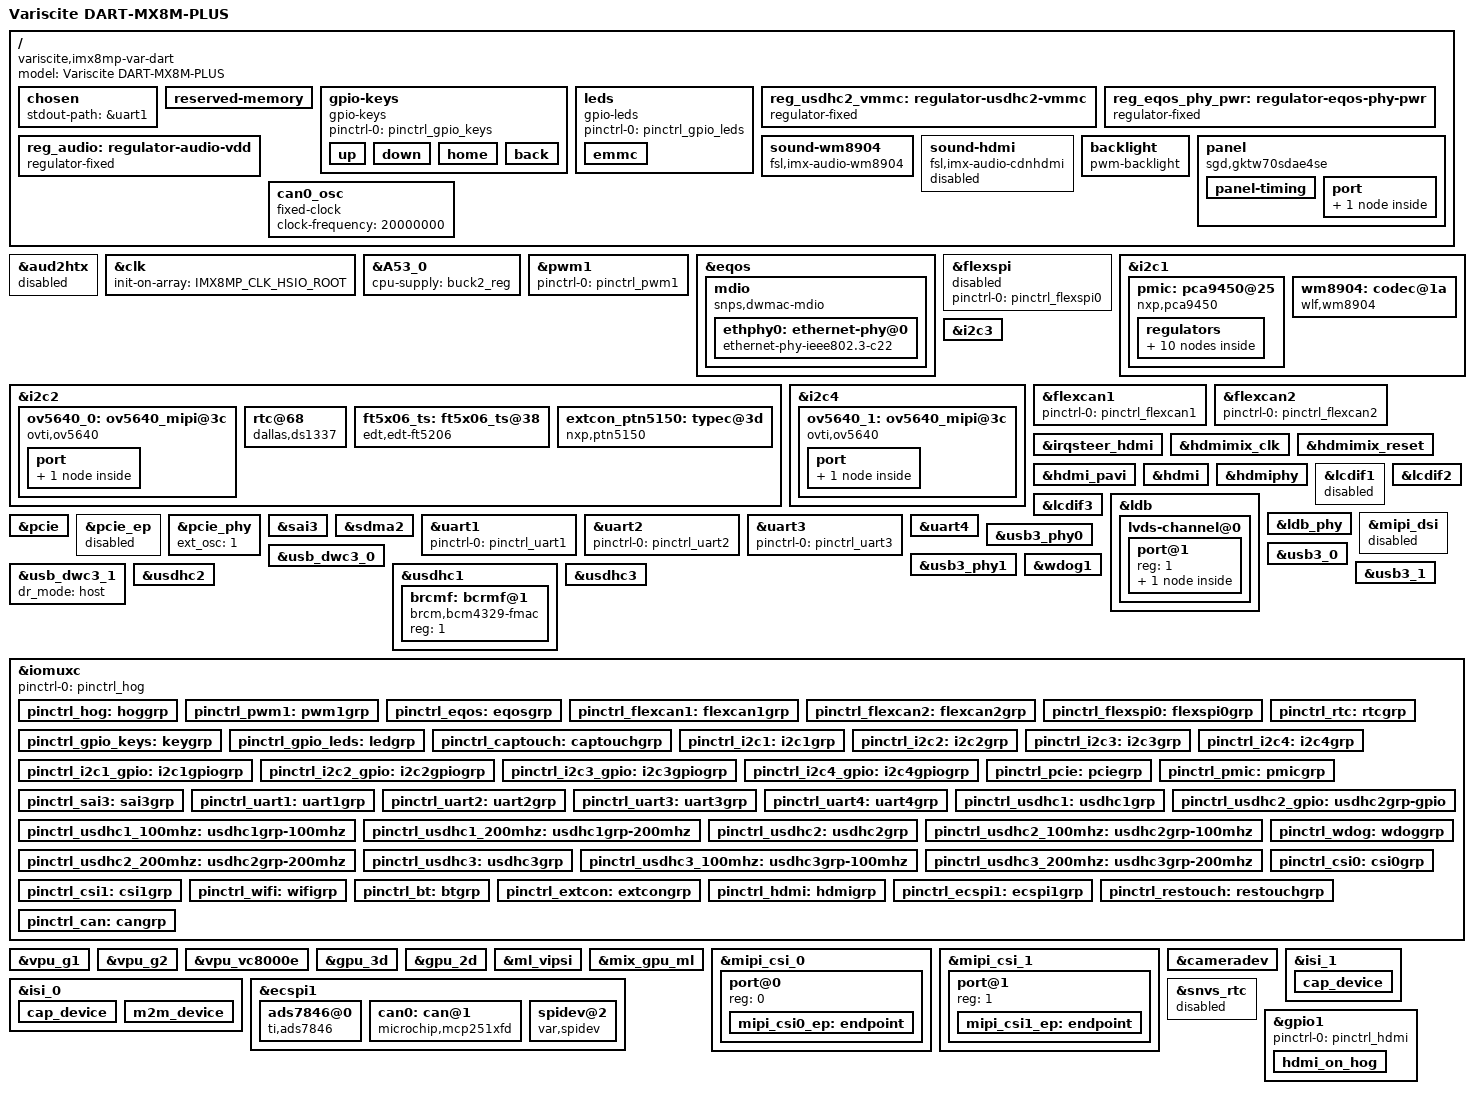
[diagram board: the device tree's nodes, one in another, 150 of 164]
// SPDX-License-Identifier: (GPL-2.0+ OR MIT)
/*
 * Copyright 2019 NXP
 * Copyright 2020 Variscite Ltd.
 */

/dts-v1/;

#include <dt-bindings/usb/pd.h>
#include "imx8mp.dtsi"

/ {
	model = "Variscite DART-MX8M-PLUS";
	compatible = "variscite,imx8mp-var-dart", "fsl,imx8mp";

	chosen {
		stdout-path = &uart1;
	};

	/delete-node/ memory@40000000;

	reserved-memory {
		/* CMA region is configured by kernel command line as cma=<size>M */
		/delete-node/ linux,cma;
	};

	gpio-keys {
		compatible = "gpio-keys";
		pinctrl-names = "default";
		pinctrl-0 = <&pinctrl_gpio_keys>;
		status = "okay";

		up {
			label = "Up";
			gpios = <&gpio4 18 GPIO_ACTIVE_LOW>;
			linux,code = <KEY_UP>;
			wakeup-source;
		};

		down {
			label = "Down";
			gpios = <&gpio4 15 GPIO_ACTIVE_LOW>;
			linux,code = <KEY_DOWN>;
			wakeup-source;
		};

		home {
			label = "Home";
			gpios = <&gpio4 13 GPIO_ACTIVE_LOW>;
			linux,code = <KEY_HOME>;
			wakeup-source;
		};

		back {
			label = "Back";
			gpios = <&gpio4 6 GPIO_ACTIVE_LOW>;
			linux,code = <KEY_BACK>;
			wakeup-source;
		};
	};

	leds {
		compatible = "gpio-leds";
		pinctrl-names = "default";
		pinctrl-0 = <&pinctrl_gpio_leds>;
		status = "okay";

		emmc {
			label = "eMMC";
			gpios = <&gpio4 17 GPIO_ACTIVE_HIGH>;
			linux,default-trigger = "mmc0";
		};
	};

	reg_usdhc2_vmmc: regulator-usdhc2-vmmc {
		compatible = "regulator-fixed";
		regulator-name = "VSD_3V3";
		regulator-min-microvolt = <3300000>;
		regulator-max-microvolt = <3300000>;
		gpio = <&gpio2 19 GPIO_ACTIVE_HIGH>;
		enable-active-high;
		startup-delay-us = <100>;
		off-on-delay-us = <12000>;
	};

	reg_eqos_phy_pwr: regulator-eqos-phy-pwr {
		compatible = "regulator-fixed";
		regulator-name = "eqos-phy-pwr";
		regulator-min-microvolt = <3300000>;
		regulator-max-microvolt = <3300000>;
		gpio = <&gpio2 20 GPIO_ACTIVE_HIGH>;
		enable-active-high;
		regulator-always-on;
	};

	reg_audio: regulator-audio-vdd {
		compatible = "regulator-fixed";
		regulator-name = "wm8904_supply";
		regulator-min-microvolt = <3300000>;
		regulator-max-microvolt = <3300000>;
		regulator-always-on;
	};

	sound-wm8904 {
		compatible = "fsl,imx-audio-wm8904";
		model = "wm8904-audio";
		audio-cpu = <&sai3>;
		audio-codec = <&wm8904>;
		audio-routing =
			"Headphone Jack", "HPOUTL",
			"Headphone Jack", "HPOUTR",
			"IN2L", "Line In Jack",
			"IN2R", "Line In Jack",
			"IN1L", "Mic Jack",
			"Playback", "CPU-Playback",
			"CPU-Capture", "Capture";
		status = "okay";
	};

	sound-hdmi {
		compatible = "fsl,imx-audio-cdnhdmi";
		model = "audio-hdmi";
		audio-cpu = <&aud2htx>;
		hdmi-out;
		constraint-rate = <44100>,
				<88200>,
				<176400>,
				<32000>,
				<48000>,
				<96000>,
				<192000>;
		status = "disabled";
	};

	backlight: backlight {
		compatible = "pwm-backlight";
		pwms = <&pwm1 0 1000000>;
		status = "okay";

		brightness-levels = < 0  1  2  3  4  5  6  7  8  9
				     10 11 12 13 14 15 16 17 18 19
				     20 21 22 23 24 25 26 27 28 29
				     30 31 32 33 34 35 36 37 38 39
				     40 41 42 43 44 45 46 47 48 49
				     50 51 52 53 54 55 56 57 58 59
				     60 61 62 63 64 65 66 67 68 69
				     70 71 72 73 74 75 76 77 78 79
				     80 81 82 83 84 85 86 87 88 89
				     90 91 92 93 94 95 96 97 98 99
				    100>;
		default-brightness-level = <80>;
	};

	panel {
		compatible = "sgd,gktw70sdae4se", "panel-lvds";
		backlight = <&backlight>;
		width-mm = <153>;
		height-mm = <87>;
		label = "gktw70sdae4se";
		data-mapping = "jeida-24";
		status = "okay";

		panel-timing {
			clock-frequency = <33000000>;
			hactive = <800>;
			vactive = <480>;
			hback-porch = <40>;
			hfront-porch = <40>;
			vback-porch = <29>;
			vfront-porch = <13>;
			hsync-len = <48>;
			vsync-len = <3>;
			hsync-active = <0>;
			vsync-active = <0>;
			de-active = <1>;
		};

		port {
			panel_in: endpoint {
				remote-endpoint = <&lvds_out>;
			};
		};
	};

	can0_osc: can0_osc {
		compatible = "fixed-clock";
		#clock-cells = <0>;
		clock-frequency = <20000000>;
	};
};

&aud2htx {
	status = "disabled";
};

&clk {
	init-on-array = <IMX8MP_CLK_HSIO_ROOT>;
};

&A53_0 {
	cpu-supply = <&buck2_reg>;
};

&pwm1 {
	pinctrl-names = "default";
	pinctrl-0 = <&pinctrl_pwm1>;
	status = "okay";
};

&eqos {
	pinctrl-names = "default";
	pinctrl-0 = <&pinctrl_eqos>;
	phy-mode = "rgmii";
	phy-handle = <&ethphy0>;
	snps,reset-gpio = <&gpio2 11 GPIO_ACTIVE_LOW>;
	snps,reset-delays-us = <100000 10000 100000>;
	mdio_rst_after_resume;
	status = "okay";

	mdio {
		compatible = "snps,dwmac-mdio";
		#address-cells = <1>;
		#size-cells = <0>;

		ethphy0: ethernet-phy@0 {
			compatible = "ethernet-phy-ieee802.3-c22";
			reg = <0>;
			at803x,eee-disabled;
			at803x,vddio-1p8v;
			eee-broken-1000t;
		};
	};
};

&flexspi {
	pinctrl-names = "default";
	pinctrl-0 = <&pinctrl_flexspi0>;
	status = "disabled";
};

&i2c1 {
	clock-frequency = <100000>;
	pinctrl-names = "default", "gpio";
	pinctrl-0 = <&pinctrl_i2c1>;
	pinctrl-1 = <&pinctrl_i2c1_gpio>;
	scl-gpios = <&gpio5 14 GPIO_ACTIVE_HIGH>;
	sda-gpios = <&gpio5 15 GPIO_ACTIVE_HIGH>;
	status = "okay";

	pmic: pca9450@25 {
		reg = <0x25>;
		compatible = "nxp,pca9450";
		pinctrl-0 = <&pinctrl_pmic>;
		gpio_intr = <&gpio1 3 IRQ_TYPE_LEVEL_LOW>;
		status = "okay";

		regulators {
			#address-cells = <1>;
			#size-cells = <0>;

			pca9450,pmic-buck2-uses-i2c-dvs;
			/* Run/Standby voltage */
			pca9450,pmic-buck2-dvs-voltage = <950000>, <850000>;

			buck1_reg: regulator@0 {
				reg = <0>;
				regulator-compatible = "buck1";
				regulator-min-microvolt = <600000>;
				regulator-max-microvolt = <2187500>;
				regulator-boot-on;
				regulator-always-on;
				regulator-ramp-delay = <3125>;
			};

			buck2_reg: regulator@1 {
				reg = <1>;
				regulator-compatible = "buck2";
				regulator-min-microvolt = <600000>;
				regulator-max-microvolt = <2187500>;
				regulator-boot-on;
				regulator-always-on;
				regulator-ramp-delay = <3125>;
			};

			buck4_reg: regulator@3 {
				reg = <3>;
				regulator-compatible = "buck4";
				regulator-min-microvolt = <600000>;
				regulator-max-microvolt = <3400000>;
				regulator-boot-on;
				regulator-always-on;
			};

			buck5_reg: regulator@4 {
				reg = <4>;
				regulator-compatible = "buck5";
				regulator-min-microvolt = <600000>;
				regulator-max-microvolt = <3400000>;
				regulator-boot-on;
				regulator-always-on;
			};

			buck6_reg: regulator@5 {
				reg = <5>;
				regulator-compatible = "buck6";
				regulator-min-microvolt = <600000>;
				regulator-max-microvolt = <3400000>;
				regulator-boot-on;
				regulator-always-on;
			};

			ldo1_reg: regulator@6 {
				reg = <6>;
				regulator-compatible = "ldo1";
				regulator-min-microvolt = <1600000>;
				regulator-max-microvolt = <3300000>;
				regulator-boot-on;
				regulator-always-on;
			};

			ldo2_reg: regulator@7 {
				reg = <7>;
				regulator-compatible = "ldo2";
				regulator-min-microvolt = <800000>;
				regulator-max-microvolt = <1150000>;
				regulator-boot-on;
				regulator-always-on;
			};

			ldo3_reg: regulator@8 {
				reg = <8>;
				regulator-compatible = "ldo3";
				regulator-min-microvolt = <800000>;
				regulator-max-microvolt = <3300000>;
				regulator-boot-on;
				regulator-always-on;
			};

			ldo4_reg: regulator@9 {
				reg = <9>;
				regulator-compatible = "ldo4";
				regulator-min-microvolt = <3300000>;
				regulator-max-microvolt = <3300000>;
				regulator-always-on;
			};

			ldo5_reg: regulator@10 {
				reg = <10>;
				regulator-compatible = "ldo5";
				regulator-min-microvolt = <1800000>;
				regulator-max-microvolt = <3300000>;
			};
		};
	};

	wm8904: codec@1a {
		compatible = "wlf,wm8904";
		reg = <0x1a>;
		clocks = <&audiomix_clk IMX8MP_CLK_AUDIOMIX_SAI3_MCLK1>;
		clock-names = "mclk";
		DCVDD-supply = <&reg_audio>;
		DBVDD-supply = <&reg_audio>;
		AVDD-supply = <&reg_audio>;
		CPVDD-supply = <&reg_audio>;
		MICVDD-supply = <&reg_audio>;
		gpio-cfg = <
			0x0018 /* GPIO1 => DMIC_CLK */
			0xffff /* GPIO2 => don't touch */
			0xffff /* GPIO3 => don't touch */
			0xffff /* GPIO4 => don't touch */
		>;
		status = "okay";
	};
};

&i2c2 {
	clock-frequency = <100000>;
	pinctrl-names = "default", "gpio";
	pinctrl-0 = <&pinctrl_i2c2>;
	pinctrl-1 = <&pinctrl_i2c2_gpio>;
	scl-gpios = <&gpio5 16 GPIO_ACTIVE_HIGH>;
	sda-gpios = <&gpio5 17 GPIO_ACTIVE_HIGH>;
	status = "okay";

	ov5640_0: ov5640_mipi@3c {
		compatible = "ovti,ov5640";
		reg = <0x3c>;
		pinctrl-names = "default";
		pinctrl-0 = <&pinctrl_csi0>;
		clocks = <&clk IMX8MP_CLK_IPP_DO_CLKO2>;
		clock-names = "xclk";
/* Disabled CLKO2, since DART-MX8MP camera expansion board uses
 * its own oscillator. Enable CLK02 if your desing requres it
 */
#if 0
		assigned-clocks = <&clk IMX8MP_CLK_IPP_DO_CLKO2>;
		assigned-clock-parents = <&clk IMX8MP_CLK_24M>;
#endif
		assigned-clock-rates = <24000000>;
		csi_id = <0>;
		powerdown-gpios = <&gpio4 8 GPIO_ACTIVE_HIGH>;
		reset-gpios = <&gpio5 28 GPIO_ACTIVE_LOW>;
		mclk = <24000000>;
		mclk_source = <0>;
		mipi_csi;
		status = "okay";

		port {
			ov5640_mipi_0_ep: endpoint {
				remote-endpoint = <&mipi_csi0_ep>;
				data-lanes = <1 2>;
				clock-lanes = <0>;
			};
		};
	};

	/* DS1337 RTC module */
	rtc@68 {
		status = "okay";
		compatible = "dallas,ds1337";
		reg = <0x68>;
		pinctrl-names = "default";
		pinctrl-0 = <&pinctrl_rtc>;
		interrupt-parent = <&gpio1>;
		interrupts = <15 IRQ_TYPE_EDGE_FALLING>;
		wakeup-source;
	};

	/* Capacitive touch controller */
	ft5x06_ts: ft5x06_ts@38 {
		status = "okay";
		compatible = "edt,edt-ft5206";
		reg = <0x38>;
		reset-gpios = <&gpio4 5 GPIO_ACTIVE_LOW>;
		pinctrl-names = "default";
		pinctrl-0 = <&pinctrl_captouch>;
		interrupt-parent = <&gpio1>;
		interrupts = <14 IRQ_TYPE_EDGE_FALLING>;
		touchscreen-size-x = <800>;
		touchscreen-size-y = <480>;
		touchscreen-inverted-x;
		touchscreen-inverted-y;
		wakeup-source;
	};

	/* USB Type-C Controller */
	extcon_ptn5150: typec@3d {
		compatible = "nxp,ptn5150";
		pinctrl-names = "default";
		pinctrl-0 = <&pinctrl_extcon>;
		reg = <0x3d>;
		int-gpio = <&gpio1 10 GPIO_ACTIVE_HIGH>;
		status ="okay";
	};
};

&i2c3 {
	clock-frequency = <100000>;
	pinctrl-names = "default", "gpio";
	pinctrl-0 = <&pinctrl_i2c3>;
	pinctrl-1 = <&pinctrl_i2c3_gpio>;
	scl-gpios = <&gpio5 18 GPIO_ACTIVE_HIGH>;
	sda-gpios = <&gpio5 19 GPIO_ACTIVE_HIGH>;
	status = "okay";
};

&i2c4 {
	clock-frequency = <100000>;
	pinctrl-names = "default", "gpio";
	pinctrl-0 = <&pinctrl_i2c4>;
	pinctrl-1 = <&pinctrl_i2c4_gpio>;
	scl-gpios = <&gpio5 20 GPIO_ACTIVE_HIGH>;
	sda-gpios = <&gpio5 21 GPIO_ACTIVE_HIGH>;
	status = "okay";

	ov5640_1: ov5640_mipi@3c {
		compatible = "ovti,ov5640";
		reg = <0x3c>;
		pinctrl-names = "default";
		pinctrl-0 = <&pinctrl_csi1>;
		clocks = <&clk IMX8MP_CLK_IPP_DO_CLKO2>;
		clock-names = "xclk";
/* Disabled CLKO2, since DART-MX8MP camera expansion board uses
 * its own oscillator. Enable CLK02 if your desing requres it
 */
#if 0
		assigned-clocks = <&clk IMX8MP_CLK_IPP_DO_CLKO2>;
		assigned-clock-parents = <&clk IMX8MP_CLK_24M>;
#endif
		assigned-clock-rates = <24000000>;
		csi_id = <1>;
		powerdown-gpios = <&gpio4 9 GPIO_ACTIVE_HIGH>;
		reset-gpios = <&gpio4 12 GPIO_ACTIVE_LOW>;
		mclk = <24000000>;
		mclk_source = <0>;
		mipi_csi;
		status = "okay";

		port {
			ov5640_mipi_1_ep: endpoint {
				remote-endpoint = <&mipi_csi1_ep>;
				data-lanes = <1 2>;
				clock-lanes = <0>;
			};
		};
	};
};

&flexcan1 {
	pinctrl-names = "default";
	pinctrl-0 = <&pinctrl_flexcan1>;
	status = "okay";
};

&flexcan2 {
	pinctrl-names = "default";
	pinctrl-0 = <&pinctrl_flexcan2>;
	status = "okay";
};

&irqsteer_hdmi {
	status = "okay";
};

&hdmimix_clk {
	status = "okay";
};

&hdmimix_reset {
	status = "okay";
};

&hdmi_pavi {
	status = "okay";
};

&hdmi {
	status = "okay";
};

&hdmiphy {
	status = "okay";
};

/* MIPI-DSI */
&lcdif1 {
	status = "disabled";
};

/* LVDS */
&lcdif2 {
	status = "okay";
};

/* HDMI */
&lcdif3 {
	status = "okay";
};

&ldb {
	status = "okay";

	lvds-channel@0 {
		fsl,data-mapping = "jeida";
		fsl,data-width = <24>;
		status = "okay";

		port@1 {
			reg = <1>;

			lvds_out: endpoint {
				remote-endpoint = <&panel_in>;
			};
		};
	};
};

&ldb_phy {
	status = "okay";
};

&mipi_dsi {
	status = "disabled";
};

&pcie {
	pinctrl-names = "default";
	pinctrl-0 = <&pinctrl_pcie>;
	reset-gpio = <&gpio4 7 GPIO_ACTIVE_LOW>;
	ext_osc = <1>;
	clocks = <&clk IMX8MP_CLK_HSIO_AXI_DIV>,
		 <&clk IMX8MP_CLK_PCIE_AUX>,
		 <&clk IMX8MP_CLK_PCIE_PHY>,
		 <&clk IMX8MP_CLK_PCIE_ROOT>;
	clock-names = "pcie", "pcie_aux", "pcie_phy", "pcie_bus";
	assigned-clocks = <&clk IMX8MP_CLK_HSIO_AXI_SRC>,
			  <&clk IMX8MP_CLK_PCIE_AUX>;
	assigned-clock-parents = <&clk IMX8MP_SYS_PLL2_500M>,
				 <&clk IMX8MP_SYS_PLL2_50M>;
	status = "okay";
};

&pcie_ep {
	pinctrl-names = "default";
	pinctrl-0 = <&pinctrl_pcie>;
	ext_osc = <1>;
	clocks = <&clk IMX8MP_CLK_HSIO_AXI_DIV>,
		 <&clk IMX8MP_CLK_PCIE_AUX>,
		 <&clk IMX8MP_CLK_PCIE_PHY>,
		 <&clk IMX8MP_CLK_PCIE_ROOT>;
	clock-names = "pcie", "pcie_aux", "pcie_phy", "pcie_bus";
	assigned-clocks = <&clk IMX8MP_CLK_HSIO_AXI_SRC>,
			  <&clk IMX8MP_CLK_PCIE_AUX>;
	assigned-clock-parents = <&clk IMX8MP_SYS_PLL2_500M>,
				 <&clk IMX8MP_SYS_PLL2_50M>;
	status = "disabled";
};

&pcie_phy {
	ext_osc = <1>;
	status = "okay";
};

&sai3 {
	pinctrl-names = "default";
	pinctrl-0 = <&pinctrl_sai3>;
	assigned-clocks = <&clk IMX8MP_CLK_SAI3>;
	assigned-clock-parents = <&clk IMX8MP_AUDIO_PLL1_OUT>;
	assigned-clock-rates = <11536000>;
	fsl,sai-mclk-direction-output;
	status = "okay";
};

&sdma2 {
	status = "okay";
};

/* Console */
&uart1 {
	pinctrl-names = "default";
	pinctrl-0 = <&pinctrl_uart1>;
	status = "okay";
};

/* Header */
&uart2 {
	pinctrl-names = "default";
	pinctrl-0 = <&pinctrl_uart2>;
	status = "okay";
};

/* Header */
&uart3 {
	pinctrl-names = "default";
	pinctrl-0 = <&pinctrl_uart3>;
	status = "okay";
};

/* BT */
&uart4 {
	pinctrl-names = "default";
	pinctrl-0 = <&pinctrl_uart4>, <&pinctrl_bt>;
	assigned-clocks = <&clk IMX8MP_CLK_UART4>;
	assigned-clock-parents = <&clk IMX8MP_SYS_PLL1_80M>;
	fsl,uart-has-rtscts;
	status = "okay";
};

&usb3_phy0 {
	status = "okay";
};

&usb3_0 {
	status = "okay";
};

&usb_dwc3_0 {
	dr_mode = "otg";
	hnp-disable;
	srp-disable;
	adp-disable;
	extcon = <&extcon_ptn5150>;
	status = "okay";
};

&usb3_phy1 {
	status = "okay";
};

&usb3_1 {
	status = "okay";
};

&usb_dwc3_1 {
	dr_mode = "host";
	status = "okay";
};

&usdhc1 {
	#address-cells = <1>;
	#size-cells = <0>;
	pinctrl-names = "default", "state_100mhz", "state_200mhz";
	pinctrl-0 = <&pinctrl_usdhc1>, <&pinctrl_wifi>;
	pinctrl-1 = <&pinctrl_usdhc1_100mhz>, <&pinctrl_wifi>;
	pinctrl-2 = <&pinctrl_usdhc1_200mhz>, <&pinctrl_wifi>;
	bus-width = <4>;
	non-removable;
	keep-power-in-suspend;
	status = "okay";

	brcmf: bcrmf@1 {
		reg = <1>;
		compatible = "brcm,bcm4329-fmac";
	};
};

&usdhc2 {
	pinctrl-names = "default", "state_100mhz", "state_200mhz";
	pinctrl-0 = <&pinctrl_usdhc2>, <&pinctrl_usdhc2_gpio>;
	pinctrl-1 = <&pinctrl_usdhc2_100mhz>, <&pinctrl_usdhc2_gpio>;
	pinctrl-2 = <&pinctrl_usdhc2_200mhz>, <&pinctrl_usdhc2_gpio>;
	cd-gpios = <&gpio2 12 GPIO_ACTIVE_LOW>;
	vmmc-supply = <&reg_usdhc2_vmmc>;
	bus-width = <4>;
	status = "okay";
};

&usdhc3 {
	pinctrl-names = "default", "state_100mhz", "state_200mhz";
	pinctrl-0 = <&pinctrl_usdhc3>;
	pinctrl-1 = <&pinctrl_usdhc3_100mhz>;
	pinctrl-2 = <&pinctrl_usdhc3_200mhz>;
	bus-width = <8>;
	non-removable;
	status = "okay";
};

&wdog1 {
	pinctrl-names = "default";
	pinctrl-0 = <&pinctrl_wdog>;
	fsl,ext-reset-output;
	status = "okay";
};

&iomuxc {
	pinctrl-names = "default";
	pinctrl-0 = <&pinctrl_hog>;

	pinctrl_hog: hoggrp {
		fsl,pins = <
			MX8MP_IOMUXC_HDMI_DDC_SCL__HDMIMIX_HDMI_SCL			0x400001c3
			MX8MP_IOMUXC_HDMI_DDC_SDA__HDMIMIX_HDMI_SDA			0x400001c3
			MX8MP_IOMUXC_HDMI_HPD__HDMIMIX_HDMI_HPD				0x40000019
			MX8MP_IOMUXC_HDMI_CEC__HDMIMIX_HDMI_CEC				0x40000019
		>;
	};

	pinctrl_pwm1: pwm1grp {
		fsl,pins = <
			MX8MP_IOMUXC_GPIO1_IO01__PWM1_OUT				0x116
		>;
	};

	pinctrl_eqos: eqosgrp {
		fsl,pins = <
			MX8MP_IOMUXC_ENET_MDC__ENET_QOS_MDC				0x3
			MX8MP_IOMUXC_ENET_MDIO__ENET_QOS_MDIO				0x3
			MX8MP_IOMUXC_ENET_RD0__ENET_QOS_RGMII_RD0			0x91
			MX8MP_IOMUXC_ENET_RD1__ENET_QOS_RGMII_RD1			0x91
			MX8MP_IOMUXC_ENET_RD2__ENET_QOS_RGMII_RD2			0x91
			MX8MP_IOMUXC_ENET_RD3__ENET_QOS_RGMII_RD3			0x91
			MX8MP_IOMUXC_ENET_RXC__CCM_ENET_QOS_CLOCK_GENERATE_RX_CLK	0x91
			MX8MP_IOMUXC_ENET_RX_CTL__ENET_QOS_RGMII_RX_CTL			0x91
			MX8MP_IOMUXC_ENET_TD0__ENET_QOS_RGMII_TD0			0x1f
			MX8MP_IOMUXC_ENET_TD1__ENET_QOS_RGMII_TD1			0x1f
			MX8MP_IOMUXC_ENET_TD2__ENET_QOS_RGMII_TD2			0x1f
			MX8MP_IOMUXC_ENET_TD3__ENET_QOS_RGMII_TD3			0x1f
			MX8MP_IOMUXC_ENET_TX_CTL__ENET_QOS_RGMII_TX_CTL			0x1f
			MX8MP_IOMUXC_ENET_TXC__CCM_ENET_QOS_CLOCK_GENERATE_TX_CLK	0x1f
			MX8MP_IOMUXC_SD1_STROBE__GPIO2_IO11				0x19
			MX8MP_IOMUXC_SD2_WP__GPIO2_IO20					0x19
		>;
	};

	pinctrl_flexcan1: flexcan1grp {
		fsl,pins = <
			MX8MP_IOMUXC_SAI5_RXD2__CAN1_RX					0x154
			MX8MP_IOMUXC_SAI5_RXD1__CAN1_TX					0x154
		>;
	};

	pinctrl_flexcan2: flexcan2grp {
		fsl,pins = <
			MX8MP_IOMUXC_SAI5_MCLK__CAN2_RX					0x154
			MX8MP_IOMUXC_SAI5_RXD3__CAN2_TX					0x154
		>;
	};

	pinctrl_flexspi0: flexspi0grp {
		fsl,pins = <
			MX8MP_IOMUXC_NAND_ALE__FLEXSPI_A_SCLK				0x1c2
			MX8MP_IOMUXC_NAND_CE0_B__FLEXSPI_A_SS0_B			0x82
			MX8MP_IOMUXC_NAND_DATA00__FLEXSPI_A_DATA00			0x82
			MX8MP_IOMUXC_NAND_DATA01__FLEXSPI_A_DATA01			0x82
			MX8MP_IOMUXC_NAND_DATA02__FLEXSPI_A_DATA02			0x82
			MX8MP_IOMUXC_NAND_DATA03__FLEXSPI_A_DATA03			0x82
		>;
	};

	pinctrl_gpio_keys: keygrp {
		fsl,pins = <
			MX8MP_IOMUXC_SAI1_TXD3__GPIO4_IO15				0x143
			MX8MP_IOMUXC_SAI1_TXD6__GPIO4_IO18				0x143
			MX8MP_IOMUXC_SAI1_TXD1__GPIO4_IO13				0x143
			MX8MP_IOMUXC_SAI1_RXD4__GPIO4_IO06				0x143
		>;
	};

	pinctrl_gpio_leds: ledgrp {
		fsl,pins = <
			MX8MP_IOMUXC_SAI1_RXD1__GPIO4_IO03				0xc6
			MX8MP_IOMUXC_SAI1_TXD2__GPIO4_IO14				0xc6
			MX8MP_IOMUXC_SAI1_RXD2__GPIO4_IO04				0xc6
			MX8MP_IOMUXC_SAI1_TXD5__GPIO4_IO17				0xc6
		>;
	};

	pinctrl_rtc: rtcgrp {
		fsl,pins = <
			MX8MP_IOMUXC_GPIO1_IO15__GPIO1_IO15 				0x1c1
		>;
	};

	pinctrl_captouch: captouchgrp {
		fsl,pins = <
			MX8MP_IOMUXC_SAI1_RXD3__GPIO4_IO05 				0x1c6
			MX8MP_IOMUXC_GPIO1_IO14__GPIO1_IO14				0x16
		>;
	};

	pinctrl_i2c1: i2c1grp {
		fsl,pins = <
			MX8MP_IOMUXC_I2C1_SCL__I2C1_SCL					0x400001c3
			MX8MP_IOMUXC_I2C1_SDA__I2C1_SDA					0x400001c3
		>;
	};

	pinctrl_i2c2: i2c2grp {
		fsl,pins = <
			MX8MP_IOMUXC_I2C2_SCL__I2C2_SCL					0x400001c3
			MX8MP_IOMUXC_I2C2_SDA__I2C2_SDA					0x400001c3
		>;
	};

	pinctrl_i2c3: i2c3grp {
		fsl,pins = <
			MX8MP_IOMUXC_I2C3_SCL__I2C3_SCL					0x400001c3
			MX8MP_IOMUXC_I2C3_SDA__I2C3_SDA					0x400001c3
		>;
	};

	pinctrl_i2c4: i2c4grp {
		fsl,pins = <
			MX8MP_IOMUXC_I2C4_SCL__I2C4_SCL					0x400001c3
			MX8MP_IOMUXC_I2C4_SDA__I2C4_SDA					0x400001c3
		>;
	};

	pinctrl_i2c1_gpio: i2c1gpiogrp {
		fsl,pins = <
			MX8MP_IOMUXC_I2C1_SCL__GPIO5_IO14				0x1c3
			MX8MP_IOMUXC_I2C1_SDA__GPIO5_IO15				0x1c3
		>;
	};

	pinctrl_i2c2_gpio: i2c2gpiogrp {
		fsl,pins = <
			MX8MP_IOMUXC_I2C2_SCL__GPIO5_IO16				0x1c3
			MX8MP_IOMUXC_I2C2_SDA__GPIO5_IO17				0x1c3
		>;
	};

	pinctrl_i2c3_gpio: i2c3gpiogrp {
		fsl,pins = <
			MX8MP_IOMUXC_I2C3_SCL__GPIO5_IO18				0x1c3
			MX8MP_IOMUXC_I2C3_SDA__GPIO5_IO19				0x1c3
		>;
	};

	pinctrl_i2c4_gpio: i2c4gpiogrp {
		fsl,pins = <
			MX8MP_IOMUXC_I2C4_SCL__GPIO5_IO20				0x1c3
			MX8MP_IOMUXC_I2C4_SDA__GPIO5_IO21				0x1c3
		>;
	};

	pinctrl_pcie: pciegrp {
		fsl,pins = <
			MX8MP_IOMUXC_SAI1_RXD5__GPIO4_IO07				0x41
		>;
	};

	pinctrl_pmic: pmicgrp {
		fsl,pins = <
			MX8MP_IOMUXC_GPIO1_IO03__GPIO1_IO03				0x1c1
		>;
	};

	pinctrl_sai3: sai3grp {
		fsl,pins = <
			MX8MP_IOMUXC_SAI3_TXFS__AUDIOMIX_SAI3_TX_SYNC			0xd6
			MX8MP_IOMUXC_SAI3_TXC__AUDIOMIX_SAI3_TX_BCLK			0xd6
			MX8MP_IOMUXC_SAI3_RXD__AUDIOMIX_SAI3_RX_DATA00			0xd6
			MX8MP_IOMUXC_SAI3_TXD__AUDIOMIX_SAI3_TX_DATA00			0xd6
			MX8MP_IOMUXC_SAI3_MCLK__AUDIOMIX_SAI3_MCLK			0xd6
			MX8MP_IOMUXC_SAI3_RXFS__AUDIOMIX_SAI3_RX_SYNC			0xd6
			MX8MP_IOMUXC_SAI3_RXC__AUDIOMIX_SAI3_RX_BCLK			0xd6
		>;
	};

	pinctrl_uart1: uart1grp {
		fsl,pins = <
			MX8MP_IOMUXC_UART1_RXD__UART1_DCE_RX				0x49
			MX8MP_IOMUXC_UART1_TXD__UART1_DCE_TX				0x49
		>;
	};

	pinctrl_uart2: uart2grp {
		fsl,pins = <
			MX8MP_IOMUXC_UART2_RXD__UART2_DCE_RX				0x49
			MX8MP_IOMUXC_UART2_TXD__UART2_DCE_TX				0x49
		>;
	};

	pinctrl_uart3: uart3grp {
		fsl,pins = <
			MX8MP_IOMUXC_UART3_RXD__UART3_DCE_RX				0x49
			MX8MP_IOMUXC_UART3_TXD__UART3_DCE_TX				0x49
		>;
	};

	pinctrl_uart4: uart4grp {
		fsl,pins = <
			MX8MP_IOMUXC_ECSPI2_SCLK__UART4_DCE_RX				0x140
			MX8MP_IOMUXC_ECSPI2_MOSI__UART4_DCE_TX				0x140
			MX8MP_IOMUXC_ECSPI2_MISO__UART4_DCE_CTS				0x140
			MX8MP_IOMUXC_ECSPI2_SS0__UART4_DCE_RTS				0x140
		>;
	};

	pinctrl_usdhc1: usdhc1grp {
		fsl,pins = <
			MX8MP_IOMUXC_SD1_CLK__USDHC1_CLK				0x190
			MX8MP_IOMUXC_SD1_CMD__USDHC1_CMD				0x1d0
			MX8MP_IOMUXC_SD1_DATA0__USDHC1_DATA0				0x1d0
			MX8MP_IOMUXC_SD1_DATA1__USDHC1_DATA1				0x1d0
			MX8MP_IOMUXC_SD1_DATA2__USDHC1_DATA2				0x1d0
			MX8MP_IOMUXC_SD1_DATA3__USDHC1_DATA3				0x1d0
		>;
	};

	pinctrl_usdhc1_100mhz: usdhc1grp-100mhz {
		fsl,pins = <
			MX8MP_IOMUXC_SD1_CLK__USDHC1_CLK				0x194
			MX8MP_IOMUXC_SD1_CMD__USDHC1_CMD				0x1d4
			MX8MP_IOMUXC_SD1_DATA0__USDHC1_DATA0				0x1d4
			MX8MP_IOMUXC_SD1_DATA1__USDHC1_DATA1				0x1d4
			MX8MP_IOMUXC_SD1_DATA2__USDHC1_DATA2				0x1d4
			MX8MP_IOMUXC_SD1_DATA3__USDHC1_DATA3				0x1d4
		>;
	};

	pinctrl_usdhc1_200mhz: usdhc1grp-200mhz {
		fsl,pins = <
			MX8MP_IOMUXC_SD1_CLK__USDHC1_CLK				0x196
			MX8MP_IOMUXC_SD1_CMD__USDHC1_CMD				0x1d6
			MX8MP_IOMUXC_SD1_DATA0__USDHC1_DATA0				0x1d6
			MX8MP_IOMUXC_SD1_DATA1__USDHC1_DATA1				0x1d6
			MX8MP_IOMUXC_SD1_DATA2__USDHC1_DATA2				0x1d6
			MX8MP_IOMUXC_SD1_DATA3__USDHC1_DATA3				0x1d6
		>;
	};

	pinctrl_usdhc2_gpio: usdhc2grp-gpio {
		fsl,pins = <
			MX8MP_IOMUXC_SD2_CD_B__GPIO2_IO12 				0x1c4
			MX8MP_IOMUXC_SD2_RESET_B__GPIO2_IO19				0x41
		>;
	};

	pinctrl_usdhc2: usdhc2grp {
		fsl,pins = <
			MX8MP_IOMUXC_SD2_CLK__USDHC2_CLK				0x190
			MX8MP_IOMUXC_SD2_CMD__USDHC2_CMD				0x1d0
			MX8MP_IOMUXC_SD2_DATA0__USDHC2_DATA0				0x1d0
			MX8MP_IOMUXC_SD2_DATA1__USDHC2_DATA1				0x1d0
			MX8MP_IOMUXC_SD2_DATA2__USDHC2_DATA2				0x1d0
			MX8MP_IOMUXC_SD2_DATA3__USDHC2_DATA3				0x1d0
			MX8MP_IOMUXC_GPIO1_IO04__USDHC2_VSELECT				0xc1
		>;
	};

	pinctrl_usdhc2_100mhz: usdhc2grp-100mhz {
		fsl,pins = <
			MX8MP_IOMUXC_SD2_CLK__USDHC2_CLK				0x194
			MX8MP_IOMUXC_SD2_CMD__USDHC2_CMD				0x1d4
			MX8MP_IOMUXC_SD2_DATA0__USDHC2_DATA0				0x1d4
			MX8MP_IOMUXC_SD2_DATA1__USDHC2_DATA1				0x1d4
			MX8MP_IOMUXC_SD2_DATA2__USDHC2_DATA2				0x1d4
			MX8MP_IOMUXC_SD2_DATA3__USDHC2_DATA3				0x1d4
			MX8MP_IOMUXC_GPIO1_IO04__USDHC2_VSELECT 			0xc1
		>;
	};

	pinctrl_usdhc2_200mhz: usdhc2grp-200mhz {
		fsl,pins = <
			MX8MP_IOMUXC_SD2_CLK__USDHC2_CLK				0x196
			MX8MP_IOMUXC_SD2_CMD__USDHC2_CMD				0x1d6
			MX8MP_IOMUXC_SD2_DATA0__USDHC2_DATA0				0x1d6
			MX8MP_IOMUXC_SD2_DATA1__USDHC2_DATA1				0x1d6
			MX8MP_IOMUXC_SD2_DATA2__USDHC2_DATA2				0x1d6
			MX8MP_IOMUXC_SD2_DATA3__USDHC2_DATA3				0x1d6
			MX8MP_IOMUXC_GPIO1_IO04__USDHC2_VSELECT 			0xc1
		>;
	};

	pinctrl_usdhc3: usdhc3grp {
		fsl,pins = <
			MX8MP_IOMUXC_NAND_WE_B__USDHC3_CLK				0x190
			MX8MP_IOMUXC_NAND_WP_B__USDHC3_CMD				0x1d0
			MX8MP_IOMUXC_NAND_DATA04__USDHC3_DATA0				0x1d0
			MX8MP_IOMUXC_NAND_DATA05__USDHC3_DATA1				0x1d0
			MX8MP_IOMUXC_NAND_DATA06__USDHC3_DATA2				0x1d0
			MX8MP_IOMUXC_NAND_DATA07__USDHC3_DATA3				0x1d0
			MX8MP_IOMUXC_NAND_RE_B__USDHC3_DATA4				0x1d0
			MX8MP_IOMUXC_NAND_CE2_B__USDHC3_DATA5				0x1d0
			MX8MP_IOMUXC_NAND_CE3_B__USDHC3_DATA6				0x1d0
			MX8MP_IOMUXC_NAND_CLE__USDHC3_DATA7				0x1d0
			MX8MP_IOMUXC_NAND_CE1_B__USDHC3_STROBE				0x190
		>;
	};

	pinctrl_usdhc3_100mhz: usdhc3grp-100mhz {
		fsl,pins = <
			MX8MP_IOMUXC_NAND_WE_B__USDHC3_CLK				0x194
			MX8MP_IOMUXC_NAND_WP_B__USDHC3_CMD				0x1d4
			MX8MP_IOMUXC_NAND_DATA04__USDHC3_DATA0				0x1d4
			MX8MP_IOMUXC_NAND_DATA05__USDHC3_DATA1				0x1d4
			MX8MP_IOMUXC_NAND_DATA06__USDHC3_DATA2				0x1d4
			MX8MP_IOMUXC_NAND_DATA07__USDHC3_DATA3				0x1d4
			MX8MP_IOMUXC_NAND_RE_B__USDHC3_DATA4				0x1d4
			MX8MP_IOMUXC_NAND_CE2_B__USDHC3_DATA5				0x1d4
			MX8MP_IOMUXC_NAND_CE3_B__USDHC3_DATA6				0x1d4
			MX8MP_IOMUXC_NAND_CLE__USDHC3_DATA7				0x1d4
			MX8MP_IOMUXC_NAND_CE1_B__USDHC3_STROBE				0x194
		>;
	};

	pinctrl_usdhc3_200mhz: usdhc3grp-200mhz {
		fsl,pins = <
			MX8MP_IOMUXC_NAND_WE_B__USDHC3_CLK				0x196
			MX8MP_IOMUXC_NAND_WP_B__USDHC3_CMD				0x1d6
			MX8MP_IOMUXC_NAND_DATA04__USDHC3_DATA0				0x1d6
			MX8MP_IOMUXC_NAND_DATA05__USDHC3_DATA1				0x1d6
			MX8MP_IOMUXC_NAND_DATA06__USDHC3_DATA2				0x1d6
			MX8MP_IOMUXC_NAND_DATA07__USDHC3_DATA3				0x1d6
			MX8MP_IOMUXC_NAND_RE_B__USDHC3_DATA4				0x1d6
			MX8MP_IOMUXC_NAND_CE2_B__USDHC3_DATA5				0x1d6
			MX8MP_IOMUXC_NAND_CE3_B__USDHC3_DATA6				0x1d6
			MX8MP_IOMUXC_NAND_CLE__USDHC3_DATA7				0x1d6
			MX8MP_IOMUXC_NAND_CE1_B__USDHC3_STROBE				0x196
		>;
	};

	pinctrl_wdog: wdoggrp {
		fsl,pins = <
			MX8MP_IOMUXC_GPIO1_IO02__WDOG1_WDOG_B				0xc6
		>;
	};

	pinctrl_csi0: csi0grp {
		fsl,pins = <
			MX8MP_IOMUXC_SAI1_RXD6__GPIO4_IO08				0x19
			MX8MP_IOMUXC_UART4_RXD__GPIO5_IO28				0x19
			>;
	};

	pinctrl_csi1: csi1grp {
		fsl,pins = <
			MX8MP_IOMUXC_SAI1_RXD7__GPIO4_IO09				0x19
			MX8MP_IOMUXC_SAI1_TXD0__GPIO4_IO12				0x19
			>;
	};

	pinctrl_wifi: wifigrp {
		fsl,pins = <
			MX8MP_IOMUXC_SD1_DATA5__GPIO2_IO07				0xc1
			MX8MP_IOMUXC_SD1_DATA6__GPIO2_IO08				0xc1
		>;
	};

	pinctrl_bt: btgrp {
		fsl,pins = <
			MX8MP_IOMUXC_SD1_DATA4__GPIO2_IO06				0xc1
			MX8MP_IOMUXC_SD1_DATA7__GPIO2_IO09				0xc1
		>;
	};

	pinctrl_extcon: extcongrp {
		fsl,pins = <
			MX8MP_IOMUXC_GPIO1_IO10__GPIO1_IO10				0x19
		>;
	};

	pinctrl_hdmi: hdmigrp {
		fsl,pins = <
			MX8MP_IOMUXC_GPIO1_IO05__GPIO1_IO05				0xc1
		>;
	};

	pinctrl_ecspi1: ecspi1grp {
		fsl,pins = <
			MX8MP_IOMUXC_ECSPI1_SCLK__ECSPI1_SCLK				0x13
			MX8MP_IOMUXC_ECSPI1_MOSI__ECSPI1_MOSI				0x13
			MX8MP_IOMUXC_ECSPI1_MISO__ECSPI1_MISO				0x13
			MX8MP_IOMUXC_ECSPI1_SS0__GPIO5_IO09				0x13
			MX8MP_IOMUXC_GPIO1_IO12__GPIO1_IO12				0x13
			MX8MP_IOMUXC_SD1_RESET_B__GPIO2_IO10				0x13
		>;
	};

	pinctrl_restouch: restouchgrp {
		fsl,pins = <
			MX8MP_IOMUXC_GPIO1_IO07__GPIO1_IO07				0xc0
		>;
	};

	pinctrl_can: cangrp {
		fsl,pins = <
			MX8MP_IOMUXC_GPIO1_IO06__GPIO1_IO06				0x1c6
		>;
	};
};

&vpu_g1 {
	status = "okay";
};

&vpu_g2 {
	status = "okay";
};

&vpu_vc8000e {
	status = "okay";
};

&gpu_3d {
	status = "okay";
};

&gpu_2d {
	status = "okay";
};

&ml_vipsi {
	status = "okay";
};

&mix_gpu_ml {
	status = "okay";
};

&mipi_csi_0 {
	#address-cells = <1>;
	#size-cells = <0>;
	status = "okay";

	port@0 {
		reg = <0>;
		mipi_csi0_ep: endpoint {
			remote-endpoint = <&ov5640_mipi_0_ep>;
			data-lanes = <2>;
			csis-hs-settle = <13>;
			csis-clk-settle = <2>;
			csis-wclk;
		};
	};
};

&mipi_csi_1 {
	#address-cells = <1>;
	#size-cells = <0>;
	status = "okay";

	port@1 {
		reg = <1>;
		mipi_csi1_ep: endpoint {
			remote-endpoint = <&ov5640_mipi_1_ep>;
			data-lanes = <2>;
			csis-hs-settle = <13>;
			csis-clk-settle = <2>;
			csis-wclk;
		};
	};
};

&cameradev {
	status = "okay";
};

&isi_0 {
	status = "okay";

	cap_device {
		status = "okay";
	};

	m2m_device {
		status = "okay";
	};
};

&isi_1 {
	status = "okay";

	cap_device {
		status = "okay";
	};
};

&ecspi1 {
	pinctrl-names = "default";
	pinctrl-0 = <&pinctrl_ecspi1>;
	cs-gpios = <&gpio5  9 GPIO_ACTIVE_LOW>,
		   <&gpio1 12 GPIO_ACTIVE_LOW>,
		   <&gpio2 10 GPIO_ACTIVE_LOW>;
	status = "okay";

	/* Resistive touch controller */
	ads7846@0 {
		reg = <0>;
		compatible = "ti,ads7846";
		pinctrl-names = "default";
		pinctrl-0 = <&pinctrl_restouch>;
		interrupt-parent = <&gpio1>;
		interrupts = <7 IRQ_TYPE_EDGE_FALLING>;
		spi-max-frequency = <1500000>;
		pendown-gpio = <&gpio1 7 GPIO_ACTIVE_LOW>;
		ti,x-min = /bits/ 16 <125>;
		ti,x-max = /bits/ 16 <4008>;
		ti,y-min = /bits/ 16 <282>;
		ti,y-max = /bits/ 16 <3864>;
		ti,x-plate-ohms = /bits/ 16 <180>;
		ti,pressure-max = /bits/ 16 <255>;
		ti,debounce-max = /bits/ 16 <10>;
		ti,debounce-tol = /bits/ 16 <3>;
		ti,debounce-rep = /bits/ 16 <1>;
		ti,settle-delay-usec = /bits/ 16 <150>;
		ti,keep-vref-on;
		wakeup-source;
		status = "okay";
	};

	can0: can@1 {
		compatible = "microchip,mcp251xfd";
		reg = <1>;
		pinctrl-names = "default";
		pinctrl-0 = <&pinctrl_can>;
		clocks = <&can0_osc>;
		interrupt-parent = <&gpio1>;
		interrupts = <6 IRQ_TYPE_LEVEL_LOW>;
		spi-max-frequency = <10000000>;
		status = "okay";
	};

	spidev@2 {
		reg = <2>;
		compatible = "var,spidev";
		spi-max-frequency = <12000000>;
		status = "okay";
	};
};

&snvs_rtc {
	status = "disabled";
};

&gpio1 {
	pinctrl-names = "default";
	pinctrl-0 = <&pinctrl_hdmi>;

	hdmi_on_hog {
		gpio-hog;
		gpios = <5 0>;
		output-low;
		line-name = "hdmi_on";
	};
};
